# PIC32CX1012BZ25032 device description
Architecture: CORTEX-M4; Family: PIC32CX; Series: BZ25
Registers are 32-bit, read-write, reset 0x0 unless marked. A register's access mark holds for its fields unless they carry their own. Offsets are from the block's base; [hi:lo] are bit positions; {n}, {i} and the like mark numbered series.

## PMU — PMU SPI controller
Instances: PMU 0x44013E00
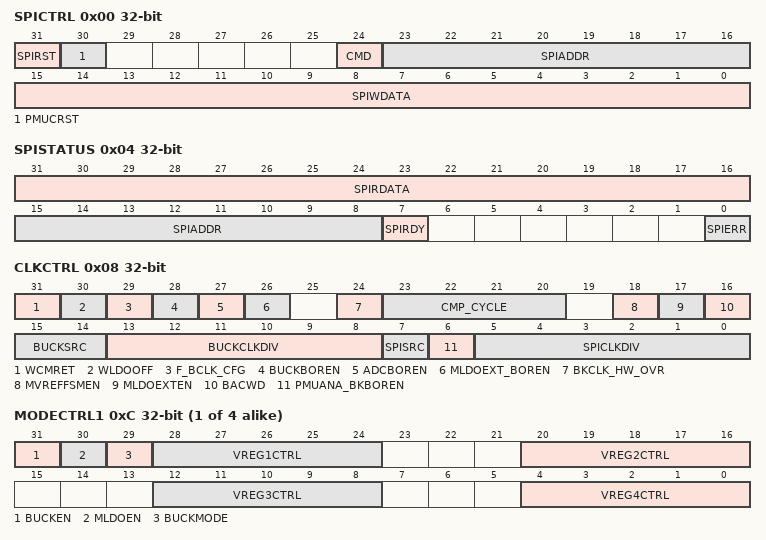
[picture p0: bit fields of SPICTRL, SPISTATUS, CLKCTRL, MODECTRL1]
0x00 SPICTRL
  [31] SPIRST, [30] PMUCRST, [24] CMD, [23:16] SPIADDR, [15:0] SPIWDATA
0x04 SPISTATUS
  [31:16] SPIRDATA, [15:8] SPIADDR, [7] SPIRDY, [0] SPIERR
0x08 CLKCTRL
  [31] WCMRET, [30] WLDOOFF, [29] F_BCLK_CFG, [28] BUCKBOREN, [27] ADCBOREN, [26] MLDOEXT_BOREN, [24] BKCLK_HW_OVR, [23:20] CMP_CYCLE, [18] MVREFFSMEN, [17] MLDOEXTEN, [16] BACWD, [15:14] BUCKSRC, [13:8] BUCKCLKDIV, [7] SPISRC, [6] PMUANA_BKBOREN, [5:0] SPICLKDIV
{0x8+4i} MODECTRL{i} (i=1..4)
  [31] BUCKEN, [30] MLDOEN, [29] BUCKMODE, [36-8n:32-8n] VREG{n}CTRL (n=1..4)
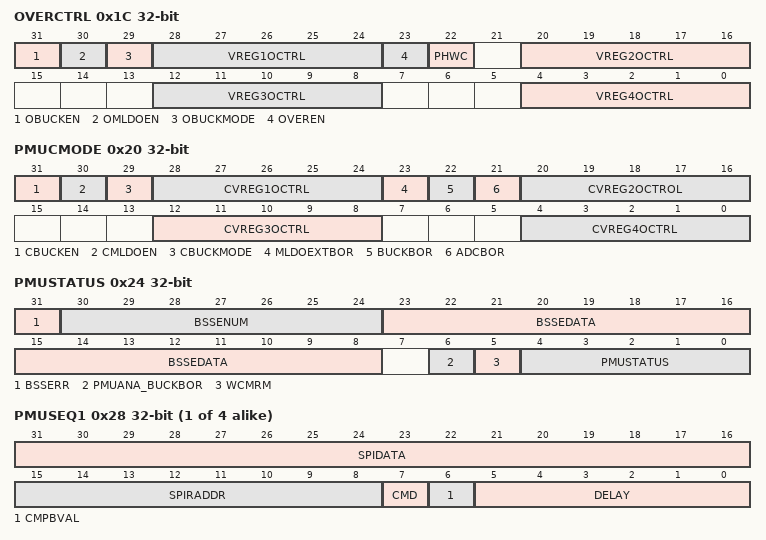
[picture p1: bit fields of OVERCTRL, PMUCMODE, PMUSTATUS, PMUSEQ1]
0x1C OVERCTRL
  [31] OBUCKEN, [30] OMLDOEN, [29] OBUCKMODE, [36-8n:32-8n] VREG{n}OCTRL (n=1..4), [23] OVEREN, [22] PHWC
0x20 PMUCMODE
  [31] CBUCKEN, [30] CMLDOEN, [29] CBUCKMODE, [28:24] CVREG1OCTRL, [23] MLDOEXTBOR, [22] BUCKBOR, [21] ADCBOR, [20:16] CVREG2OCTROL, [12:8] CVREG3OCTRL, [4:0] CVREG4OCTRL
0x24 PMUSTATUS
  [31] BSSERR, [30:24] BSSENUM, [23:8] BSSEDATA, [6] PMUANA_BUCKBOR, [5] WCMRM, [4:0] PMUSTATUS
{0x24+4i} PMUSEQ{i} (i=1..4)
  [31:16] SPIDATA, [15:8] SPIRADDR, [7] CMD, [6] CMPBVAL, [5:0] DELAY
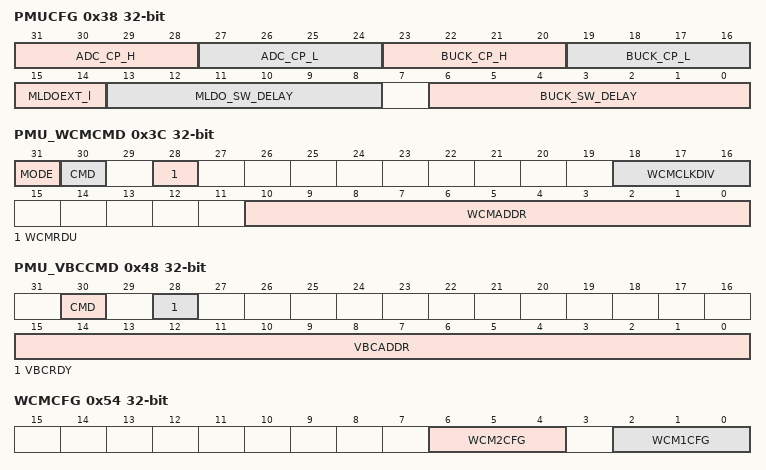
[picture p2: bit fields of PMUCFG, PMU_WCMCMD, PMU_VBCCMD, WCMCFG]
0x38 PMUCFG
  [31:28] ADC_CP_H, [27:24] ADC_CP_L, [23:20] BUCK_CP_H, [19:16] BUCK_CP_L, [15:14] MLDOEXT_l, [13:8] MLDO_SW_DELAY, [6:0] BUCK_SW_DELAY
0x3C PMU_WCMCMD
  [31] MODE, [30] CMD, [28] WCMRDU, [18:16] WCMCLKDIV, [10:0] WCMADDR
0x40 PMU_WCMWDATA
0x44 PMU_WCMRDATA
0x48 PMU_VBCCMD
  [30] CMD, [28] VBCRDY, [15:0] VBCADDR
0x4C PMU_VBCWDATA
0x50 PMU_VBCRDATA
0x54 WCMCFG
  [6:4] WCM2CFG, [2:0] WCM1CFG
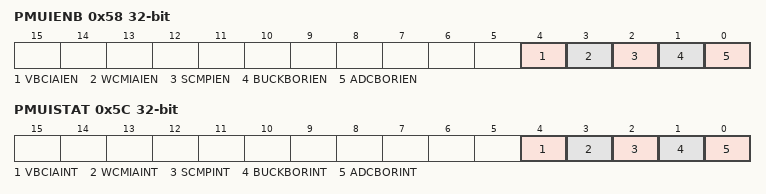
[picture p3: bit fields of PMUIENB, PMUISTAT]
0x58 PMUIENB
  [4] VBCIAIEN, [3] WCMIAIEN, [2] SCMPIEN, [1] BUCKBORIEN, [0] ADCBORIEN
0x5C PMUISTAT
  [4] VBCIAINT, [3] WCMIAINT, [2] SCMPINT, [1] BUCKBORINT, [0] ADCBORINT

## RAMECC
Instances: RAMECC 0x41008000
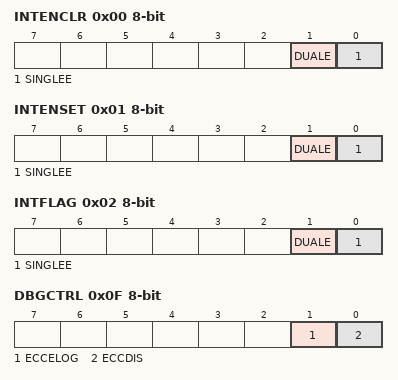
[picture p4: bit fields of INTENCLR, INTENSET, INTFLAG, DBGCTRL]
0x00 INTENCLR 8-bit (atomic clear) — Interrupt Enable Clear
  [1] DUALE — Dual Bit ECC Error Interrupt Enable Clear
  [0] SINGLEE — Single Bit ECC Error Interrupt Enable Clear
0x01 INTENSET 8-bit (atomic set) — Interrupt Enable Set
  [1] DUALE — Dual Bit ECC Error Interrupt Enable Set
  [0] SINGLEE — Single Bit ECC Error Interrupt Enable Set
0x02 INTFLAG 8-bit (atomic clear) — Interrupt Flag
  [1] DUALE — Dual Bit ECC Error Interrupt
  [0] SINGLEE — Single Bit ECC Error Interrupt
0x03 STATUS 8-bit ro
  [0] ECCDIS — ECC Disable
0x04 ERRADDR ro — Error Address
  [17:0] ERRADDR
0x0F DBGCTRL 8-bit — Debug Control
  [1] ECCELOG — ECC Error Log
  [0] ECCDIS — ECC Disable

## TRNG — True Random Generator
Instances: TRNG 0x42002800
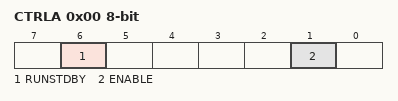
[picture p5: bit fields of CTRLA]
0x00 CTRLA 8-bit — Control A
  [6] RUNSTDBY — Run in Standby
  [1] ENABLE
0x04 EVCTRL 8-bit — Event Control
  [0] DATARDYEO — Data Ready Event Output
0x08 INTENCLR 8-bit (atomic clear) — Interrupt Enable Clear
  [0] DATARDY — Data Ready Interrupt Enable
0x09 INTENSET 8-bit (atomic set) — Interrupt Enable Set
  [0] DATARDY — Data Ready Interrupt Enable
0x0A INTFLAG 8-bit (atomic clear) — Interrupt Flag Status and Clear
  [0] DATARDY — Data Ready Interrupt Flag
0x20 DATA ro — Output Data

## WDT — Watch Dog Timer
Instances: WDT 0x44000500
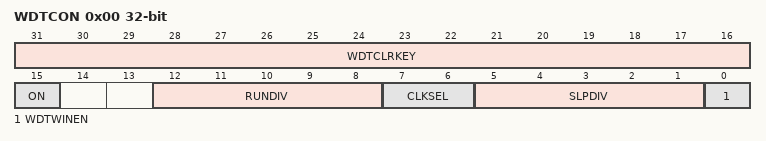
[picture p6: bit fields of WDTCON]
0x00 WDTCON reset not defined — Watchdog Timer Control Register
  [31:16] WDTCLRKEY
  [15] ON — Watchdog Timer Enable bit
    1=WDTEN (The WDT module is enabled); 0=WDTOFF (The WDT module is disabled)
  [12:8] RUNDIV
  [7:6] CLKSEL
  [5:1] SLPDIV
  [0] WDTWINEN — Watchdog Timer Window Enable bit
    1=WDTWINEN (Enable windowed Watchdog Timer); 0=WDTWINDIS (Disable windowed Watchdog Timer)
0x04 WDTCONCLR
0x08 WDTCONSET
0x0C WDTCONINV

## ARB — Radio Arbiter
Instances: ARB 0x41011000
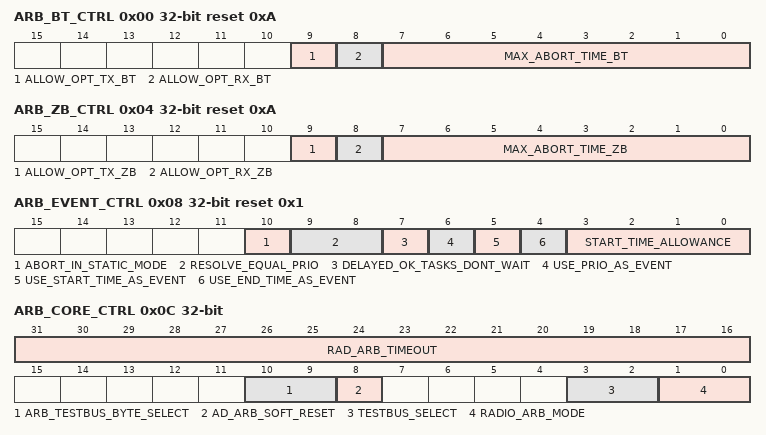
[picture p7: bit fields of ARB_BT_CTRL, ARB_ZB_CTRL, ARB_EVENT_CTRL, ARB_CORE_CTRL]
0x00 ARB_BT_CTRL reset 0xA
  [9] ALLOW_OPT_TX_BT — BT allow optimistic tx
  [8] ALLOW_OPT_RX_BT — BT allow optimistic rx
  [7:0] MAX_ABORT_TIME_BT — BT max abort time
0x04 ARB_ZB_CTRL reset 0xA
  [9] ALLOW_OPT_TX_ZB — ZB allow optimistic tx
  [8] ALLOW_OPT_RX_ZB — ZB allow optimistic rx
  [7:0] MAX_ABORT_TIME_ZB — ZB max abort time
0x08 ARB_EVENT_CTRL reset 0x1
  [10] ABORT_IN_STATIC_MODE
  [9:8] RESOLVE_EQUAL_PRIO
  [7] DELAYED_OK_TASKS_DONT_WAIT
  [6] USE_PRIO_AS_EVENT
  [5] USE_START_TIME_AS_EVENT
  [4] USE_END_TIME_AS_EVENT
  [3:0] START_TIME_ALLOWANCE — minimum change needed in the start time to be considered as an arbitration event.
0x0C ARB_CORE_CTRL
  [31:16] RAD_ARB_TIMEOUT, [10:9] ARB_TESTBUS_BYTE_SELECT, [8] AD_ARB_SOFT_RESET, [3:2] TESTBUS_SELECT, [1:0] RADIO_ARB_MODE
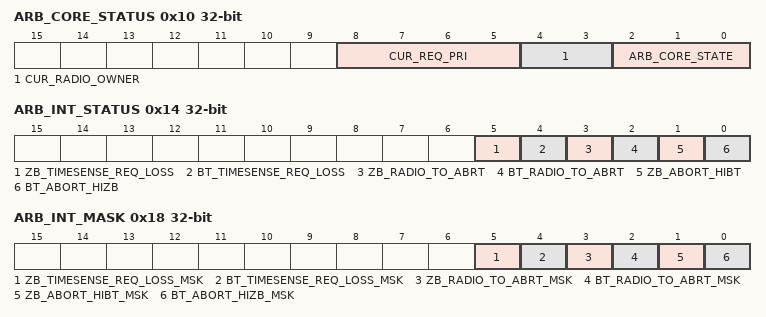
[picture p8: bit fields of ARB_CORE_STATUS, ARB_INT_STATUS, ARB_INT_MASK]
0x10 ARB_CORE_STATUS ro
  [8:5] CUR_REQ_PRI, [4:3] CUR_RADIO_OWNER, [2:0] ARB_CORE_STATE
0x14 ARB_INT_STATUS
  [5] ZB_TIMESENSE_REQ_LOSS, [4] BT_TIMESENSE_REQ_LOSS, [3] ZB_RADIO_TO_ABRT, [2] BT_RADIO_TO_ABRT, [1] ZB_ABORT_HIBT, [0] BT_ABORT_HIZB
0x18 ARB_INT_MASK
  [5] ZB_TIMESENSE_REQ_LOSS_MSK, [4] BT_TIMESENSE_REQ_LOSS_MSK, [3] ZB_RADIO_TO_ABRT_MSK, [2] BT_RADIO_TO_ABRT_MSK, [1] ZB_ABORT_HIBT_MSK, [0] BT_ABORT_HIZB_MSK

## Notices in the file
Copyright (c) 2017 Microchip Technology Inc.
SPDX-License-Identifier: Apache-2.0
Licensed under the Apache License, Version 2.0 (the "License"); you may
not use this file except in compliance with the License.
You may obtain a copy of the Licence at
http://www.apache.org/licenses/LICENSE-2.0
Unless required by applicable law or agreed to in writing, software
distributed under the License is distributed on an AS IS BASIS, WITHOUT
WARRANTIES OR CONDITIONS OF ANY KIND, either express or implied.
See the License for the specific language governing permissions and
limitations under the License.
